# RN8XXX_V2 register map
File version: 1.0
Registers are 32-bit, read-write, reset 0x0 unless marked. A register's access mark holds for its fields unless they carry their own. Offsets are from the block's base; [hi:lo] are bit positions; {n}, {i} and the like mark numbered series; 'fields as' and 'values as' point back to an identical list.

## ISO7816 — ISO7816 interface
Base 0x40038000
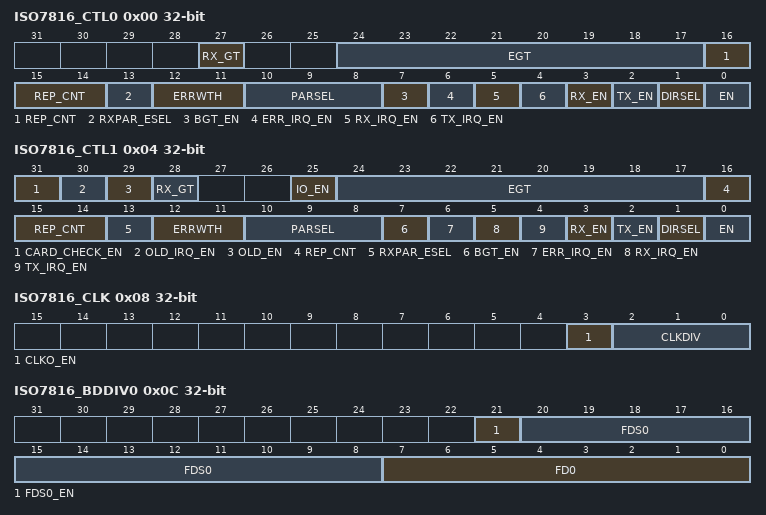
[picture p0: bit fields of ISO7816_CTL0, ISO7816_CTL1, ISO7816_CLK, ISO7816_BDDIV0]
0x00 ISO7816_CTL0 — ISO7816 No.0 control
  [27] RX_GT — receive GT width
    1=1etu (receive GT is 1 etu); 0=2etu (receive GT is 2 etu)
  [24:17] EGT — EGT width selection (in etu)
  [16:14] REP_CNT — retry times when parity error found
    0=do not retry last error transfer; {v}=retry last error transfer {v} time (v=1..7)
  [13] RXPAR_ESEL — receive parity error handling selection
    0=no_error_send (do not send error signal, but generate a interrupt request and set RX_PAR_ERR flag); 1=error_send (send error signal, generate a interrupt request and set RX_PAR_ERR flag)
  [12:11] ERRWTH — error signal width selection.applicable for RXPAR_ESEL=1 when receive
    0=2_etu; 1=1_etu; 2=1.5_etu; 3=2_etu
  [10:8] PARSEL — parity selection
    0=no_parity; 1=odd_parity; 2=even_parity; 3=stick_zero_parity (parity always zero); 4=stick_one_parity (parity always one); 5=user_defined_parity1; 6=user_defined_parity2; 7=user_defined_parity3
  [7] BGT_EN — BGT enable
    0=disable (do not generate insert BGT(22etu) between transfers); 1=enable (generate insert BGT(22etu) between transfers)
  [6] ERR_IRQ_EN — transfer error interrupt enable
    0=disable (do not generate interrupt on transfer error event); 1=enable (generate interrupt on transfer error event)
  [5] RX_IRQ_EN — receive interrupt enable
    0=disable (do not generate interrupt on receive event); 1=enable (generate interrupt on receive event)
  [4] TX_IRQ_EN — transmit interrupt enable
    0=disable (do not generate interrupt on transmit event); 1=enable (generate interrupt on transmit event)
  [3] RX_EN — receive enable
    0=disable receive; 1=enable receive
  [2] TX_EN — transmit enable
    0=disable transmit; 1=enable transmit
  [1] DIRSEL — data encode and transfer direction selection
    0=LSB (data transfered with LSB first); 1=MSB (data toggled and transfered with MSB first)
  [0] EN — controller enable
    0=disable tranceiver; 1=enable tranceiver
0x04 ISO7816_CTL1 — ISO7816 No.1 control
  [31] CARD_CHECK_EN — card draw detection enable.only when CARD_CHECK_EN and OLD_IRQ_EN enable at the same time ,CARD_OUT interrupt enable.
    0=disable (do not generate interrupt request on card draw event); 1=enable (generate interrupt request on card draw event)
  [30] OLD_IRQ_EN — OLD detection interrupt enable
    0=disable (do not generate interrupt request on OLD detection event); 1=enable (generate interrupt request on OLD detection event)
  [29] OLD_EN — OLD detection enable
    0=disable (do not detect OLD); 1=enable (detect OLD)
  [28] RX_GT — receive GT width
    1=1etu (receive GT is 1 etu); 0=2etu (receive GT is 2 etu)
  [25] IO_EN — input output enable
    0=output (78161_IO used as output); 1=input_output (78161_IO used as input and output)
  [24:17] EGT — EGT width selection (in etu)
  [16:14] REP_CNT — retry times when parity error found
    values as ISO7816_CTL0.REP_CNT
  [13] RXPAR_ESEL — receive parity error handling selection
    values as ISO7816_CTL0.RXPAR_ESEL
  [12:11] ERRWTH — error signal width selection.applicable for RXPAR_ESEL=1 when receive
    0=2_etu; 1=1_etu; 2=1.5_etu; 3=2_etu
  [10:8] PARSEL — parity selection
    values as ISO7816_CTL0.PARSEL
  [7] BGT_EN — BGT enable
    values as ISO7816_CTL0.BGT_EN
  [6] ERR_IRQ_EN — transfer error interrupt enable
    values as ISO7816_CTL0.ERR_IRQ_EN
  [5] RX_IRQ_EN — receive interrupt enable
    values as ISO7816_CTL0.RX_IRQ_EN
  [4] TX_IRQ_EN — transmit interrupt enable
    values as ISO7816_CTL0.TX_IRQ_EN
  [3] RX_EN — receive enable
    0=disable receive; 1=enable receive
  [2] TX_EN — transmit enable
    0=disable transmit; 1=enable transmit
  [1] DIRSEL — data encode and transfer direction selection
    values as ISO7816_CTL0.DIRSEL
  [0] EN — controller enable
    0=disable tranceiver; 1=enable tranceiver
0x08 ISO7816_CLK — ISO7816 clock controller register.
  [3] CLKO_EN — clock output enable
    0=disable (do not output clock to card); 1=enable (output clock to card)
  [2:0] CLKDIV — frequency divisor for output clock
    0=div1 (divisor is 1); 1=div2 (divisor is 2); 2=div4 (divisor is 4); 3=div8 (divisor is 8); 4=div16 (divisor is 16); 5=div32 (divisor is 32); 6=div64 (divisor is 64); 7=div128 (divisor is 128)
0x0C ISO7816_BDDIV0 — baudrate coefficients
  [21] FDS0_EN — F/D config enable
    0=disable (FDS0 is read-only); 1=enable (FDS0 is writable through software)
  [20:8] FDS0 — baudrate coefficient.Only writtalbe when FSD0_EN=1.otherwise read as 372
  [7:0] FD0 — FI and DI of reset ACK response
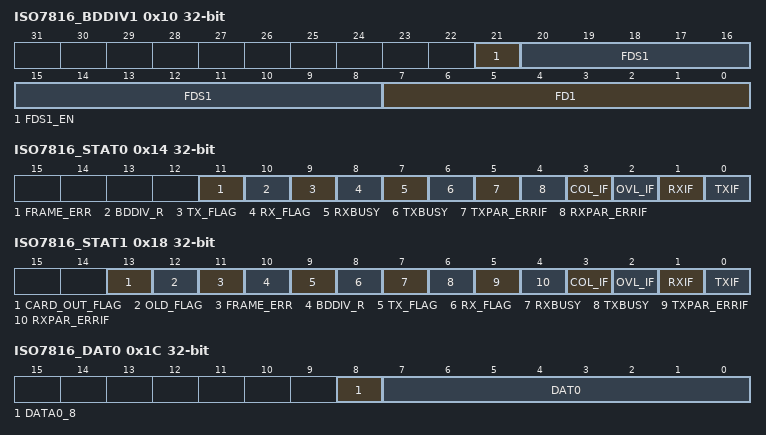
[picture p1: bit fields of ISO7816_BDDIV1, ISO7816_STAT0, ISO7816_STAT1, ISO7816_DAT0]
0x10 ISO7816_BDDIV1 — ISO7816 baud rate coefficient register1.
  [21] FDS1_EN — F/D config enable
    0=disable (FDS1 is read-only); 1=enable (FDS1 is writable through software)
  [20:8] FDS1 — baudrate coefficient.Only writtalbe when FSD1_EN=1.otherwise read as 372
  [7:0] FD1 — FI and DI of reset ACK response
0x14 ISO7816_STAT0 — ISO7816 No.0 status
  [11] FRAME_ERR write-1-clears — frame error event
    0=no (no outstanding frame error error event); 1=pending (frame error event pending)
  [10] BDDIV_R ro — baudrate match flag
    0=mismatch (baudrate mismatch); 1=match (baudrate match)
  [9] TX_FLAG ro — transmit buffer empty
    0=full (data waiting for transmitting); 1=empty (no data waiting for transmitting)
  [8] RX_FLAG ro — receive buffer full
    0=empty (no data received); 1=full (data received)
  [7] RXBUSY ro — receive busy
    0=idle (no outstanding receive in operation); 1=busy (receive in operation)
  [6] TXBUSY ro — transmit busy
    0=idle (no outstanding transmit in operation); 1=busy (transmit in operation)
  [5] TXPAR_ERRIF write-1-clears — transmit parity error event
    0=no (no outstanding transmit parity error event); 1=pending (transmit parity error event pending)
  [4] RXPAR_ERRIF write-1-clears — receive parity error event
    0=no (no outstanding receive parity error event); 1=pending (receive parity error event pending)
  [3] COL_IF write-1-clears — collision event
    0=no (no outstanding collision event); 1=pending (collision event pending)
  [2] OVL_IF write-1-clears — overflow event
    0=no (no outstanding overflow event); 1=pending (overflow event pending)
  [1] RXIF write-1-clears — receive event
    0=no (no outstanding receive event); 1=pending (receive event pending)
  [0] TXIF write-1-clears — transmit event
    0=no (no outstanding transmit event); 1=pending (transmit event pending)
0x18 ISO7816_STAT1 — ISO7816 NO.1 status
  [13] CARD_OUT_FLAG write-1-clears — card draw event
    0=no (no outstanding card draw event); 1=pending (card draw event pending)
  [12] OLD_FLAG write-1-clears — OLD detection event
    0=no (no outstanding OLD detection event); 1=pending (OLD detection event pending)
  [11] FRAME_ERR write-1-clears — frame error event
    values as ISO7816_STAT0.FRAME_ERR
  [10] BDDIV_R ro — baudrate match flag
    0=mismatch (baudrate mismatch); 1=match (baudrate match)
  [9] TX_FLAG ro — transmit buffer empty
    values as ISO7816_STAT0.TX_FLAG
  [8] RX_FLAG ro — receive buffer full
    0=empty (no data received); 1=full (data received)
  [7] RXBUSY ro — receive busy
    values as ISO7816_STAT0.RXBUSY
  [6] TXBUSY ro — transmit busy
    values as ISO7816_STAT0.TXBUSY
  [5] TXPAR_ERRIF ro write-1-clears — transmit parity error event
    values as ISO7816_STAT0.TXPAR_ERRIF
  [4] RXPAR_ERRIF write-1-clears — receive parity error event
    values as ISO7816_STAT0.RXPAR_ERRIF
  [3] COL_IF write-1-clears — collision event
    values as ISO7816_STAT0.COL_IF
  [2] OVL_IF write-1-clears — overflow event
    values as ISO7816_STAT0.OVL_IF
  [1] RXIF write-1-clears — receive event
    values as ISO7816_STAT0.RXIF
  [0] TXIF write-1-clears — transmit event
    values as ISO7816_STAT0.TXIF
0x1C ISO7816_DAT0 — ISO7816 No.0 data
  [8] DATA0_8 — parity.write as user-defined parity,read as received parity
  [7:0] DAT0 — write to transmit,read as receive
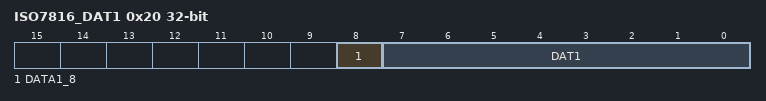
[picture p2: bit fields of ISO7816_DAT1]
0x20 ISO7816_DAT1 — ISO7816 No.1 data
  [8] DATA1_8 — parity.write as user-defined parity,read as received parity
  [7:0] DAT1 — write to transmit,read as receive
